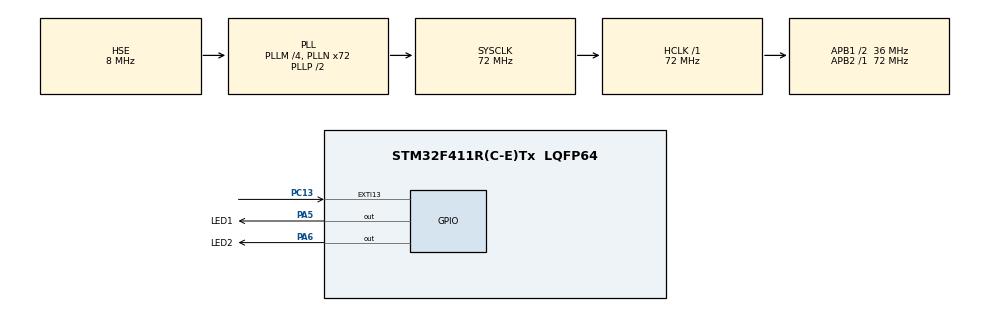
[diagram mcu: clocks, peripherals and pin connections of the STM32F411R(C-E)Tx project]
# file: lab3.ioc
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FREERTOS.Tasks01=defaultTask,0,128,StartDefaultTask,Default,NULL,Dynamic,NULL,NULL
FREERTOS.configUSE_NEWLIB_REENTRANT=0
Mcu.Family=STM32F4
Mcu.Name=STM32F411R(C-E)Tx
Mcu.Package=LQFP64
NVIC.EXTI15_10_IRQn=true\:5\:0\:false\:false\:true\:true\:true\:true
NVIC.PriorityGroup=NVIC_PRIORITYGROUP_4
NVIC.TIM1_UP_TIM10_IRQn=true\:15\:0\:false\:false\:true\:false\:false\:true
NVIC.TimeBase=TIM1_UP_TIM10_IRQn
NVIC.TimeBaseIP=TIM1
PA5.GPIO_Label=LED1
PA5.Signal=GPIO_Output
PA6.GPIO_Label=LED2
PA6.Signal=GPIO_Output
PC13-ANTI_TAMP.Signal=GPXTI13
PH0\ -\ OSC_IN.Mode=HSE-External-Oscillator
PH0\ -\ OSC_IN.Signal=RCC_OSC_IN
PH1\ -\ OSC_OUT.Mode=HSE-External-Oscillator
PH1\ -\ OSC_OUT.Signal=RCC_OSC_OUT
ProjectManager.HeapSize=0x200
ProjectManager.StackSize=0x400
ProjectManager.TargetToolchain=STM32CubeIDE
RCC.48MHZClocksFreq_Value=36000000
RCC.AHBFreq_Value=72000000
RCC.APB1CLKDivider=RCC_HCLK_DIV2
RCC.APB1Freq_Value=36000000
RCC.APB1TimFreq_Value=72000000
RCC.APB2Freq_Value=72000000
RCC.APB2TimFreq_Value=72000000
RCC.CortexFreq_Value=72000000
RCC.HCLKFreq_Value=72000000
RCC.HSE_VALUE=8000000
RCC.HSI_VALUE=16000000
RCC.LSE_VALUE=32768
RCC.PLLM=4
RCC.PLLN=72
RCC.PLLSourceVirtual=RCC_PLLSOURCE_HSE
RCC.SYSCLKFreq_VALUE=72000000
RCC.SYSCLKSource=RCC_SYSCLKSOURCE_PLLCLK
RCC.VCOOutputFreq_Value=144000000
VP_FREERTOS_VS_CMSIS_V1.Mode=CMSIS_V1
VP_SYS_VS_tim1.Mode=TIM1
board=custom

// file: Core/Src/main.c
/* USER CODE BEGIN Header */
/**
  ******************************************************************************
  * @file           : main.c
  * @brief          : Main program body
  ******************************************************************************
  * @attention
  *
  * Copyright (c) 2022 STMicroelectronics.
  * All rights reserved.
  *
  * This software is licensed under terms that can be found in the LICENSE file
  * in the root directory of this software component.
  * If no LICENSE file comes with this software, it is provided AS-IS.
  *
  ******************************************************************************
  */
/* USER CODE END Header */
#include "main.h"
#include "cmsis_os.h"

/* USER CODE BEGIN PTD */
typedef struct TaskParam
{
	GPIO_PinState state1;
	GPIO_PinState state2;
}TaskParam_t;
/* USER CODE END PTD */

osThreadId defaultTaskHandle;
/* USER CODE BEGIN PV */
SemaphoreHandle_t xSemaphore;

uint8_t flag = 0;
int indx = 0;
/* USER CODE END PV */

void SystemClock_Config(void);
static void MX_GPIO_Init(void);
void StartDefaultTask(void const * argument);

/* USER CODE BEGIN PFP */
void Button(void * argument);
void Led(void * argument);
void LedWrite(uint8_t flag, TaskParam_t param);
/* USER CODE END PFP */

int main(void)
{

  /* MCU Configuration--------------------------------------------------------*/

  /* Reset of all peripherals, Initializes the Flash interface and the Systick. */
  HAL_Init();

  /* Configure the system clock */
  SystemClock_Config();

  /* Initialize all configured peripherals */
  MX_GPIO_Init();

  /* USER CODE BEGIN RTOS_SEMAPHORES */
  /* add semaphores, ... */
  xSemaphore = xSemaphoreCreateBinary();
  /* USER CODE END RTOS_SEMAPHORES */

  /* Create the thread(s) */
  /* definition and creation of defaultTask */
  osThreadDef(defaultTask, StartDefaultTask, osPriorityNormal, 0, 128);
  defaultTaskHandle = osThreadCreate(osThread(defaultTask), NULL);

  /* USER CODE BEGIN RTOS_THREADS */
  /* add threads, ... */
  if (xSemaphore != NULL)
  {
	  xTaskCreate(Button, "Button", 128, NULL, 2, NULL);
	  xTaskCreate(Led, "Led", 128, NULL, 1, NULL);
  }
  /* USER CODE END RTOS_THREADS */

  /* Start scheduler */
  osKernelStart();

  /* We should never get here as control is now taken by the scheduler */
  /* Infinite loop */
  while (1)
  {

  }
}

void SystemClock_Config(void)
{
  RCC_OscInitTypeDef RCC_OscInitStruct = {0};
  RCC_ClkInitTypeDef RCC_ClkInitStruct = {0};

  /** Configure the main internal regulator output voltage
  */
  __HAL_RCC_PWR_CLK_ENABLE();
  __HAL_PWR_VOLTAGESCALING_CONFIG(PWR_REGULATOR_VOLTAGE_SCALE1);
  /** Initializes the RCC Oscillators according to the specified parameters
  * in the RCC_OscInitTypeDef structure.
  */
  RCC_OscInitStruct.OscillatorType = RCC_OSCILLATORTYPE_HSE;
  RCC_OscInitStruct.HSEState = RCC_HSE_ON;
  RCC_OscInitStruct.PLL.PLLState = RCC_PLL_ON;
  RCC_OscInitStruct.PLL.PLLSource = RCC_PLLSOURCE_HSE;
  RCC_OscInitStruct.PLL.PLLM = 4;
  RCC_OscInitStruct.PLL.PLLN = 72;
  RCC_OscInitStruct.PLL.PLLP = RCC_PLLP_DIV2;
  RCC_OscInitStruct.PLL.PLLQ = 4;
  if (HAL_RCC_OscConfig(&RCC_OscInitStruct) != HAL_OK)
  {
    Error_Handler();
  }
  /** Initializes the CPU, AHB and APB buses clocks
  */
  RCC_ClkInitStruct.ClockType = RCC_CLOCKTYPE_HCLK|RCC_CLOCKTYPE_SYSCLK
                              |RCC_CLOCKTYPE_PCLK1|RCC_CLOCKTYPE_PCLK2;
  RCC_ClkInitStruct.SYSCLKSource = RCC_SYSCLKSOURCE_PLLCLK;
  RCC_ClkInitStruct.AHBCLKDivider = RCC_SYSCLK_DIV1;
  RCC_ClkInitStruct.APB1CLKDivider = RCC_HCLK_DIV2;
  RCC_ClkInitStruct.APB2CLKDivider = RCC_HCLK_DIV1;

  if (HAL_RCC_ClockConfig(&RCC_ClkInitStruct, FLASH_LATENCY_2) != HAL_OK)
  {
    Error_Handler();
  }
}

static void MX_GPIO_Init(void)
{
  GPIO_InitTypeDef GPIO_InitStruct = {0};

  /* GPIO Ports Clock Enable */
  __HAL_RCC_GPIOC_CLK_ENABLE();
  __HAL_RCC_GPIOH_CLK_ENABLE();
  __HAL_RCC_GPIOA_CLK_ENABLE();

  /*Configure GPIO pin Output Level */
  HAL_GPIO_WritePin(GPIOA, LED1_Pin|LED2_Pin, GPIO_PIN_RESET);

  /*Configure GPIO pin : PC13 */
  GPIO_InitStruct.Pin = GPIO_PIN_13;
  GPIO_InitStruct.Mode = GPIO_MODE_IT_RISING;
  GPIO_InitStruct.Pull = GPIO_NOPULL;
  HAL_GPIO_Init(GPIOC, &GPIO_InitStruct);

  /*Configure GPIO pins : LED1_Pin LED2_Pin */
  GPIO_InitStruct.Pin = LED1_Pin|LED2_Pin;
  GPIO_InitStruct.Mode = GPIO_MODE_OUTPUT_PP;
  GPIO_InitStruct.Pull = GPIO_NOPULL;
  GPIO_InitStruct.Speed = GPIO_SPEED_FREQ_LOW;
  HAL_GPIO_Init(GPIOA, &GPIO_InitStruct);

  /* EXTI interrupt init*/
  HAL_NVIC_SetPriority(EXTI15_10_IRQn, 5, 0);
  HAL_NVIC_EnableIRQ(EXTI15_10_IRQn);

}

/* USER CODE BEGIN 4 */
void HAL_GPIO_EXTI_Callback(uint16_t GPIO_Pin)
{
	static BaseType_t xHigherPriorityTaskWoken;
	if (GPIO_Pin == GPIO_PIN_13)
	{
		HAL_NVIC_DisableIRQ(EXTI15_10_IRQn);
		xHigherPriorityTaskWoken = pdFALSE;
		xSemaphoreGiveFromISR(xSemaphore, &xHigherPriorityTaskWoken);
		portYIELD_FROM_ISR(xHigherPriorityTaskWoken);
	}
}

void Button(void * argument)
{
	for(;;)
	{
		if (xSemaphoreTake(xSemaphore, portMAX_DELAY) == pdPASS)
		{
			__HAL_GPIO_EXTI_CLEAR_IT(GPIO_PIN_13);
			NVIC_ClearPendingIRQ(EXTI15_10_IRQn);
			HAL_NVIC_EnableIRQ(EXTI15_10_IRQn);
			osDelay(350);
			flag++;
			if (flag > 1) flag = 0;
		}
	}
}
void Led(void * argument)
{
	TaskParam_t LedParam[4] = {{GPIO_PIN_SET,GPIO_PIN_RESET},{GPIO_PIN_SET,GPIO_PIN_SET},{GPIO_PIN_RESET,GPIO_PIN_SET},{GPIO_PIN_RESET,GPIO_PIN_RESET}};
	for(;;)
	{
		LedWrite(flag, LedParam[indx]);
	}
}
void LedWrite(uint8_t flag, TaskParam_t param)
{
	TaskParam_t parameter;
	parameter.state1 = param.state1;
	parameter.state2 = param.state2;
	switch(flag)
	{
	case 0:
		HAL_GPIO_WritePin(GPIOA, LED1_Pin, parameter.state1);
		HAL_GPIO_WritePin(GPIOA, LED2_Pin, parameter.state2);
		osDelay(250);
		indx++;
		if (indx > 3) indx = 0;
		break;
	case 1:
		HAL_GPIO_WritePin(GPIOA, LED1_Pin, parameter.state1);
		HAL_GPIO_WritePin(GPIOA, LED2_Pin, parameter.state2);
	}
}
/* USER CODE END 4 */

void StartDefaultTask(void const * argument)
{
  for(;;)
  {
    osDelay(1);
  }
}

void HAL_TIM_PeriodElapsedCallback(TIM_HandleTypeDef *htim)
{
  if (htim->Instance == TIM1) {
    HAL_IncTick();
  }
}

void Error_Handler(void)
{
  __disable_irq();
  while (1)
  {
  }
}
